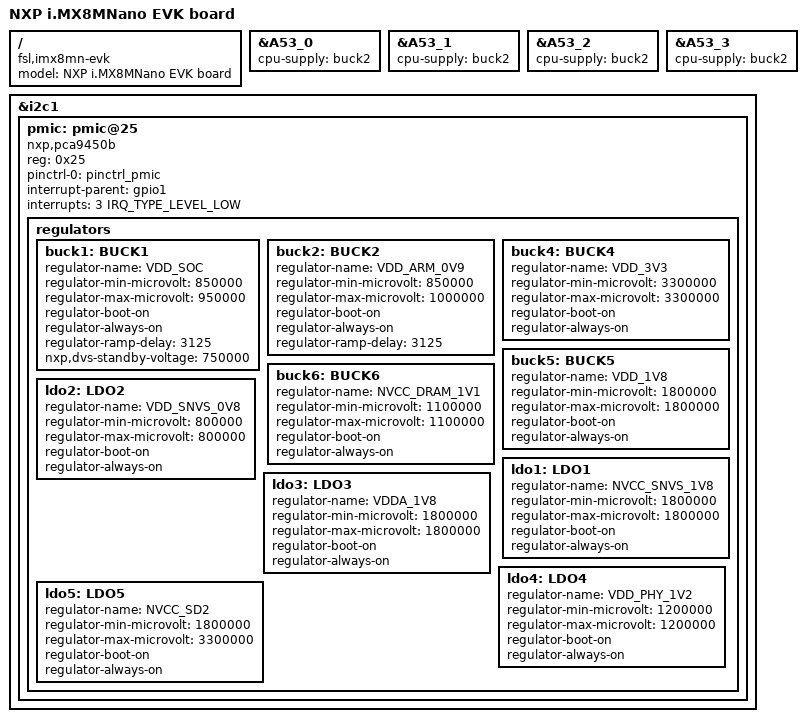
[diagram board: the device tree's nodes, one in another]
// SPDX-License-Identifier: (GPL-2.0+ OR MIT)
/*
 * Copyright 2019 NXP
 */

/dts-v1/;

#include "imx8mn.dtsi"
#include "imx8mn-evk.dtsi"
#include <dt-bindings/interrupt-controller/irq.h>

/ {
	model = "NXP i.MX8MNano EVK board";
	compatible = "fsl,imx8mn-evk", "fsl,imx8mn";
};

&A53_0 {
	cpu-supply = <&buck2>;
};

&A53_1 {
	cpu-supply = <&buck2>;
};

&A53_2 {
	cpu-supply = <&buck2>;
};

&A53_3 {
	cpu-supply = <&buck2>;
};

&i2c1 {
	pmic: pmic@25 {
		compatible = "nxp,pca9450b";
		reg = <0x25>;
		pinctrl-names = "default";
		pinctrl-0 = <&pinctrl_pmic>;
		interrupt-parent = <&gpio1>;
		interrupts = <3 IRQ_TYPE_LEVEL_LOW>;

		regulators {
			buck1: BUCK1 {
				regulator-name = "VDD_SOC";
				regulator-min-microvolt = <850000>;
				regulator-max-microvolt = <950000>;
				regulator-boot-on;
				regulator-always-on;
				regulator-ramp-delay = <3125>;
				nxp,dvs-standby-voltage = <750000>;
			};

			buck2: BUCK2 {
				regulator-name = "VDD_ARM_0V9";
				regulator-min-microvolt = <850000>;
				regulator-max-microvolt = <1000000>;
				regulator-boot-on;
				regulator-always-on;
				regulator-ramp-delay = <3125>;
			};

			buck4: BUCK4 {
				regulator-name = "VDD_3V3";
				regulator-min-microvolt = <3300000>;
				regulator-max-microvolt = <3300000>;
				regulator-boot-on;
				regulator-always-on;
			};

			buck5: BUCK5 {
				regulator-name = "VDD_1V8";
				regulator-min-microvolt = <1800000>;
				regulator-max-microvolt = <1800000>;
				regulator-boot-on;
				regulator-always-on;
			};

			buck6: BUCK6 {
				regulator-name = "NVCC_DRAM_1V1";
				regulator-min-microvolt = <1100000>;
				regulator-max-microvolt = <1100000>;
				regulator-boot-on;
				regulator-always-on;
			};

			ldo1: LDO1 {
				regulator-name = "NVCC_SNVS_1V8";
				regulator-min-microvolt = <1800000>;
				regulator-max-microvolt = <1800000>;
				regulator-boot-on;
				regulator-always-on;
			};

			ldo2: LDO2 {
				regulator-name = "VDD_SNVS_0V8";
				regulator-min-microvolt = <800000>;
				regulator-max-microvolt = <800000>;
				regulator-boot-on;
				regulator-always-on;
			};

			ldo3: LDO3 {
				regulator-name = "VDDA_1V8";
				regulator-min-microvolt = <1800000>;
				regulator-max-microvolt = <1800000>;
				regulator-boot-on;
				regulator-always-on;
			};

			ldo4: LDO4 {
				regulator-name = "VDD_PHY_1V2";
				regulator-min-microvolt = <1200000>;
				regulator-max-microvolt = <1200000>;
				regulator-boot-on;
				regulator-always-on;
			};

			ldo5: LDO5 {
				regulator-name = "NVCC_SD2";
				regulator-min-microvolt = <1800000>;
				regulator-max-microvolt = <3300000>;
				regulator-boot-on;
				regulator-always-on;
			};
		};
	};
};
